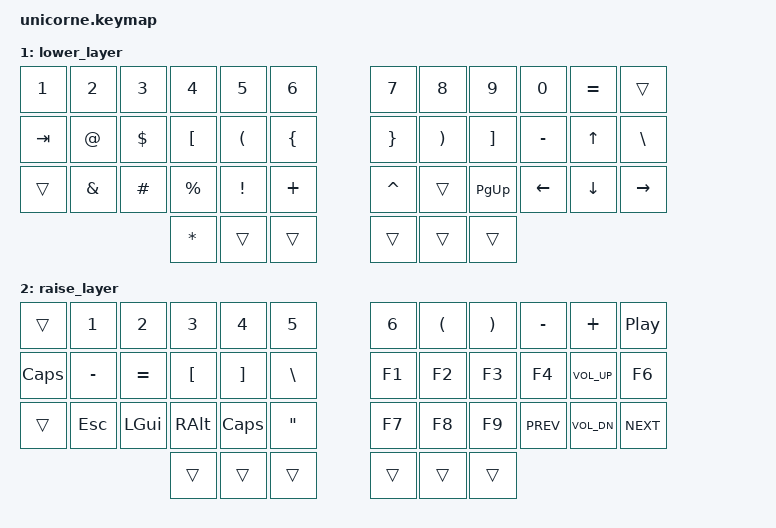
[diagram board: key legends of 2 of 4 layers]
/*
 * Copyright (c) 2020 The ZMK Contributors
 *
 * SPDX-License-Identifier: MIT
 */
#pragma once

#include <behaviors.dtsi>
#include <dt-bindings/zmk/keys.h>
#include <dt-bindings/zmk/bt.h>
#include <dt-bindings/zmk/outputs.h>
#include <dt-bindings/zmk/rgb.h>
#include <dt-bindings/zmk/backlight.h>

/ {
    macros {
        email: email {
            label = "my_email";
            compatible = "zmk,behavior-macro";
            wait-ms = <5>;
            tap-ms = <5>;
            #binding-cells = <0>;
            bindings
                = <&macro_tap &kp F &kp A &kp B &kp I &kp A &kp N>
                , <&macro_tap &kp DOT>
                , <&macro_tap &kp G &kp E &kp B &kp H &kp A &kp R &kp T>
                , <&macro_tap &kp AT>
                , <&macro_tap &kp G &kp M &kp A &kp I &kp L>
                , <&macro_tap &kp DOT>
                , <&macro_tap &kp C &kp O &kp M>
                ;
        };
    };
};

/ {
    keymap {
        compatible = "zmk,keymap";

        default_layer {
            bindings = <
// |----------+----------+----------+----------+----------+----------|                        |----------+----------+----------+----------+----------+----------|
     &kp ESC         &kp Q    &kp W    &kp E    &kp R    &kp T                                &kp Y    &kp U    &kp I    &kp O    &kp P    &kp BSPC
// |----------+----------+----------+----------+----------+----------|                        |----------+----------+----------+----------+----------+----------|
     &mt LCTRL GRAVE &kp A    &kp S    &kp D    &kp F    &kp G                                &kp H    &kp J    &kp K    &kp L    &kp SEMI &kp SQT
// |----------+----------+----------+----------+----------+----------|                        |----------+----------+----------+----------+----------+----------|
     &kp LSHFT       &kp Z    &kp X    &kp C    &kp V    &kp B                                &kp N    &kp M    &kp COMMA &kp DOT &kp FSLH &kp RSHFT
// |----------+----------+----------+----------+----------+----------+----------|  |----------+----------+----------+----------+----------+----------+----------|
                                                &kp LGUI  &mt LALT SPACE &lt 3 RET  &lt 1 SPACE &lt 2 BSLH
//                                             |----------+----------+----------|  |----------+----------+----------|
            >;
        };

        lower_layer {
            bindings = <
// |----------+----------+----------+----------+----------+----------|                        |----------+----------+----------+----------+----------+----------|
     &kp N1    &kp N2    &kp N3    &kp N4    &kp N5    &kp N6                                &kp N7    &kp N8    &kp N9    &kp N0    &kp EQUAL &trans
// |----------+----------+----------+----------+----------+----------|                        |----------+----------+----------+----------+----------+----------|
     &kp TAB   &kp AT    &kp DLLR  &kp LBKT  &kp LPAR  &kp LBRC                              &kp RBRC  &kp RPAR  &kp RBKT  &kp MINUS &kp UP    &kp BSLH
// |----------+----------+----------+----------+----------+----------|                        |----------+----------+----------+----------+----------+----------|
     &trans    &kp AMPS  &kp HASH  &kp PRCNT &kp EXCL  &kp PLUS                              &kp CARET &trans    &kp PG_UP &kp LEFT  &kp DOWN  &kp RIGHT
// |----------+----------+----------+----------+----------+----------+----------|  |----------+----------+----------+----------+----------+----------+----------|
                                                &kp STAR  &trans    &trans        &trans     &trans     &trans
//                                             |----------+----------+----------|  |----------+----------+----------|
            >;
        };

        raise_layer {
            bindings = <
// |----------+----------+----------+----------+----------+----------|                        |----------+----------+----------+----------+----------+----------|
     &trans   &kp N1    &kp N2    &kp N3    &kp N4    &kp N5                                &kp N6    &kp LPAR &kp RPAR &kp MINUS  &kp PLUS     &kp C_PLAY_PAUSE
// |----------+----------+----------+----------+----------+----------|                        |----------+----------+----------+----------+----------+----------|
     &kp CLCK &kp MINUS &kp EQUAL &kp LBKT  &kp RBKT  &kp BSLH                              &kp F1    &kp F2   &kp F3   &kp F4     &kp C_VOL_UP &kp F6
// |----------+----------+----------+----------+----------+----------|                        |----------+----------+----------+----------+----------+----------|
     &trans   &kp ESC   &kp LGUI  &kp RALT  &kp CLCK  &kp DQT                               &kp F7    &kp F8   &kp F9   &kp C_PREV &kp C_VOL_DN &kp C_NEXT
// |----------+----------+----------+----------+----------+----------+----------|  |----------+----------+----------+----------+----------+----------+----------|
                                                &trans   &trans    &trans        &trans     &trans     &trans
//                                             |----------+----------+----------|  |----------+----------+----------|
            >;
        };

        adjust_layer {
            bindings = <
// |----------+----------+----------+----------+----------+----------|                        |----------+----------+----------+----------+----------+----------|
     &out OUT_BLE &bt BT_SEL 0 &bt BT_SEL 1 &bt BT_SEL 2 &bt BT_SEL 3 &bt BT_SEL 4            &none &none &none &none &none &bt BT_CLR
// |----------+----------+----------+----------+----------+----------|                        |----------+----------+----------+----------+----------+----------|
     &out OUT_USB &none        &none        &none        &none        &none                  &none &none &none &none &none &none
// |----------+----------+----------+----------+----------+----------|                        |----------+----------+----------+----------+----------+----------|
     &rgb_ug RGB_TOG &rgb_ug RGB_BRD &rgb_ug RGB_BRI &rgb_ug RGB_EFR &rgb_ug RGB_EFF &rgb_ug RGB_HUD &rgb_ug RGB_HUI &rgb_ug RGB_SAD &rgb_ug RGB_SAI &rgb_ug RGB_SPD &rgb_ug RGB_SPI &rgb_ug RGB_TOG
// |----------+----------+----------+----------+----------+----------+----------|  |----------+----------+----------+----------+----------+----------+----------|
                                                &bl BL_TOG &bl BL_CYCLE &trans       &bl BL_DEC &bl BL_INC
//                                             |----------+----------+----------|  |----------+----------+----------|
            >;
        };
    };
};
